# ATSAMA5D27 register map
Vendor: Microchip Technology Inc.; File version: 1.0
CPU: CA5 r0p1, little endian, no MPU, no FPU, 4 interrupt priority bits
Address unit: 32 bits
Registers are 32-bit, read-write, reset 0x0 unless marked. A register's access mark holds for its fields unless they carry their own. Offsets are from the block's base; [hi:lo] are bit positions; 'fields as' and 'values as' point back to an identical list.

## RTC — Real-time Clock
Base 0xF80480B0
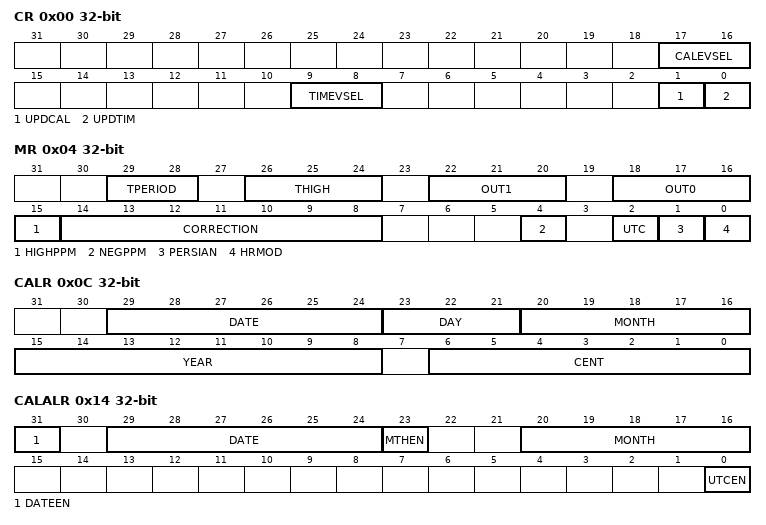
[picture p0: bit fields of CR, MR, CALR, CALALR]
0x00 CR — Control Register
  [17:16] CALEVSEL — Calendar Event Selection
    0=WEEK (Week change (every Monday at time 00:00:00)); 1=MONTH (Month change (every 01 of each month at time 00:00:00)); 2=YEAR (Year change (every January 1 at time 00:00:00))
  [9:8] TIMEVSEL — Time Event Selection
    0=MINUTE (Minute change); 1=HOUR (Hour change); 2=MIDNIGHT (Every day at midnight); 3=NOON (Every day at noon)
  [1] UPDCAL — Update Request Calendar Register
  [0] UPDTIM — Update Request Time Register
0x04 MR — Mode Register
  [29:28] TPERIOD — Period of the Output Pulse
    0=P_1S (1 second); 1=P_500MS (500 ms); 2=P_250MS (250 ms); 3=P_125MS (125 ms)
  [26:24] THIGH — High Duration of the Output Pulse
    0=H_31MS (31.2 ms); 1=H_16MS (15.6 ms); 2=H_4MS (3.91 ms); 3=H_976US (976 us); 4=H_488US (488 us); 5=H_122US (122 us); 6=H_30US (30.5 us); 7=H_15US (15.2 us)
  [22:20] OUT1 — ADC Last Channel Trigger Event Source Selection
    0=NO_WAVE (No waveform, stuck at '0'); 1=FREQ1HZ (1 Hz square wave); 2=FREQ32HZ (32 Hz square wave); 3=FREQ64HZ (64 Hz square wave); 4=FREQ512HZ (512 Hz square wave); 5=ALARM_TOGGLE (Output toggles when alarm flag rises); 6=ALARM_FLAG (Output is a copy of the alarm flag); 7=PROG_PULSE (Duty cycle programmable pulse)
  [18:16] OUT0 — All ADC Channel Trigger Event Source Selection
    values as OUT1
  [15] HIGHPPM — HIGH PPM Correction
  [14:8] CORRECTION — Slow Clock Correction
  [4] NEGPPM — NEGative PPM Correction
  [2] UTC — UTC Time Format
  [1] PERSIAN — PERSIAN Calendar
  [0] HRMOD — 12-/24-hour Mode
0x08 TIMR — Time Register
  [22] AMPM — Ante Meridiem Post Meridiem Indicator
  [21:16] HOUR — Current Hour
  [14:8] MIN — Current Minute
  [6:0] SEC — Current Second
  [31:0] UTC_TIME — Current UTC Time
0x0C CALR — Calendar Register
  [29:24] DATE — Current Day in Current Month
  [23:21] DAY — Current Day in Current Week
  [20:16] MONTH — Current Month
  [15:8] YEAR — Current Year
  [6:0] CENT — Current Century
0x10 TIMALR — Time Alarm Register
  [23] HOUREN — Hour Alarm Enable
  [22] AMPM — AM/PM Indicator
  [21:16] HOUR — Hour Alarm
  [15] MINEN — Minute Alarm Enable
  [14:8] MIN — Minute Alarm
  [7] SECEN — Second Alarm Enable
  [6:0] SEC — Second Alarm
  [31:0] UTC_TIME — UTC_TIME Alarm
0x14 CALALR — Calendar Alarm Register
  [31] DATEEN — Date Alarm Enable
  [29:24] DATE — Date Alarm
  [23] MTHEN — Month Alarm Enable
  [20:16] MONTH — Month Alarm
  [0] UTCEN — UTC Alarm Enable
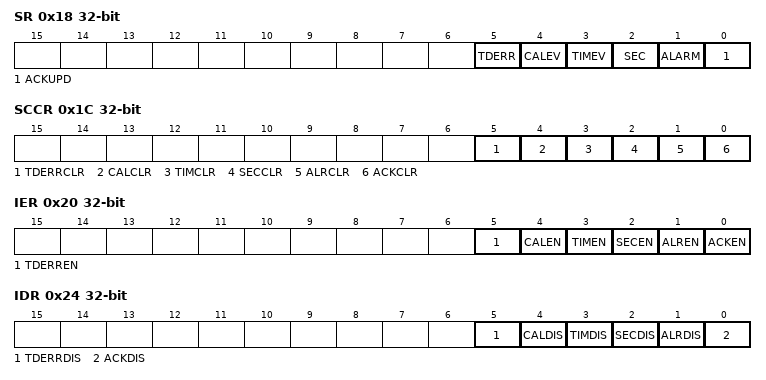
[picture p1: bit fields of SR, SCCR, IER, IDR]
0x18 SR ro — Status Register
  [5] TDERR rw — Time and/or Date Free Running Error
    0=CORRECT (The internal free running counters are carrying valid values since the last read of the Status Register (RTC_SR).); 1=ERR_TIMEDATE (The internal free running counters have been corrupted (invalid date or time, non-BCD values) since the last read and/or they are still invalid.)
  [4] CALEV rw — Calendar Event
    0=NO_CALEVENT (No calendar event has occurred since the last clear.); 1=CALEVENT (At least one calendar event has occurred since the last clear.)
  [3] TIMEV rw — Time Event
    0=NO_TIMEVENT (No time event has occurred since the last clear.); 1=TIMEVENT (At least one time event has occurred since the last clear.)
  [2] SEC rw — Second Event
    0=NO_SECEVENT (No second event has occurred since the last clear.); 1=SECEVENT (At least one second event has occurred since the last clear.)
  [1] ALARM rw — Alarm Flag
    0=NO_ALARMEVENT (No alarm matching condition occurred.); 1=ALARMEVENT (An alarm matching condition has occurred.)
  [0] ACKUPD rw — Acknowledge for Update
    0=FREERUN (Time and calendar registers cannot be updated.); 1=UPDATE (Time and calendar registers can be updated.)
0x1C SCCR wo — Status Clear Command Register
  [5] TDERRCLR rw — Time and/or Date Free Running Error Clear
  [4] CALCLR rw — Calendar Clear
  [3] TIMCLR rw — Time Clear
  [2] SECCLR rw — Second Clear
  [1] ALRCLR rw — Alarm Clear
  [0] ACKCLR rw — Acknowledge Clear
0x20 IER wo — Interrupt Enable Register
  [5] TDERREN rw — Time and/or Date Error Interrupt Enable
  [4] CALEN rw — Calendar Event Interrupt Enable
  [3] TIMEN rw — Time Event Interrupt Enable
  [2] SECEN rw — Second Event Interrupt Enable
  [1] ALREN rw — Alarm Interrupt Enable
  [0] ACKEN rw — Acknowledge Update Interrupt Enable
0x24 IDR wo — Interrupt Disable Register
  [5] TDERRDIS rw — Time and/or Date Error Interrupt Disable
  [4] CALDIS rw — Calendar Event Interrupt Disable
  [3] TIMDIS rw — Time Event Interrupt Disable
  [2] SECDIS rw — Second Event Interrupt Disable
  [1] ALRDIS rw — Alarm Interrupt Disable
  [0] ACKDIS rw — Acknowledge Update Interrupt Disable
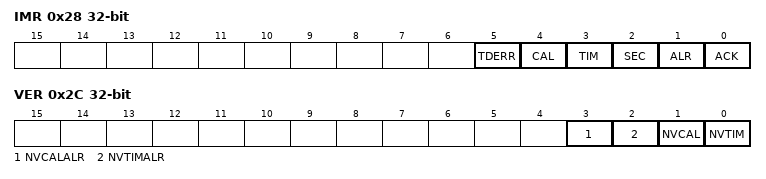
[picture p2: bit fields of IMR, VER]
0x28 IMR ro — Interrupt Mask Register
  [5] TDERR rw — Time and/or Date Error Mask
  [4] CAL rw — Calendar Event Interrupt Mask
  [3] TIM rw — Time Event Interrupt Mask
  [2] SEC rw — Second Event Interrupt Mask
  [1] ALR rw — Alarm Interrupt Mask
  [0] ACK rw — Acknowledge Update Interrupt Mask
0x2C VER ro — Valid Entry Register
  [3] NVCALALR rw — Non-valid Calendar Alarm
  [2] NVTIMALR rw — Non-valid Time Alarm
  [1] NVCAL rw — Non-valid Calendar
  [0] NVTIM rw — Non-valid Time
